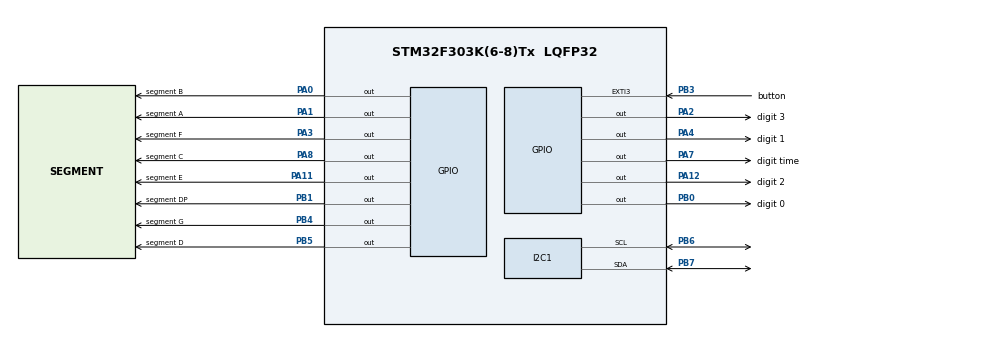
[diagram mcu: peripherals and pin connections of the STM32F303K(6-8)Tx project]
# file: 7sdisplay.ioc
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Mcu.Family=STM32F3
Mcu.Name=STM32F303K(6-8)Tx
Mcu.Package=LQFP32
NVIC.EXTI3_IRQn=true\:0\:0\:false\:false\:true\:true\:true
NVIC.I2C1_EV_IRQn=true\:0\:0\:false\:false\:true\:true\:true
NVIC.PriorityGroup=NVIC_PRIORITYGROUP_4
PA0.GPIO_Label=segment B
PA0.Signal=GPIO_Output
PA1.GPIO_Label=segment A
PA1.Signal=GPIO_Output
PA11.GPIO_Label=segment E
PA11.Signal=GPIO_Output
PA12.GPIO_Label=digit 2
PA12.Signal=GPIO_Output
PA2.GPIO_Label=digit 3
PA2.Signal=GPIO_Output
PA3.GPIO_Label=segment F
PA3.Signal=GPIO_Output
PA4.GPIO_Label=digit 1
PA4.Signal=GPIO_Output
PA7.GPIO_Label=digit time
PA7.Signal=GPIO_Output
PA8.GPIO_Label=segment C
PA8.Signal=GPIO_Output
PB0.GPIO_Label=digit 0
PB0.Signal=GPIO_Output
PB1.GPIO_Label=segment DP
PB1.Signal=GPIO_Output
PB3.GPIO_Label=button
PB3.Signal=GPXTI3
PB4.GPIO_Label=segment G
PB4.Signal=GPIO_Output
PB5.GPIO_Label=segment D
PB5.Signal=GPIO_Output
PB6.Mode=I2C
PB6.Signal=I2C1_SCL
PB7.Mode=I2C
PB7.Signal=I2C1_SDA
ProjectManager.HeapSize=0x200
ProjectManager.StackSize=0x400
ProjectManager.TargetToolchain=STM32CubeIDE
RCC.AHBFreq_Value=8000000
RCC.APB1Freq_Value=8000000
RCC.APB2Freq_Value=8000000
RCC.CortexFreq_Value=8000000
RCC.HSE_VALUE=8000000
RCC.HSI_VALUE=8000000
RCC.SYSCLKFreq_VALUE=8000000
board=custom

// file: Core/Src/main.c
/* USER CODE BEGIN Header */
/**
 ******************************************************************************
 * @file           : main.c
 * @brief          : Main program body
 ******************************************************************************
 * @attention
 *
 * <h2><center>&copy; Copyright (c) 2020 STMicroelectronics.
 * All rights reserved.</center></h2>
 *
 * This software component is licensed by ST under BSD 3-Clause license,
 * the "License"; You may not use this file except in compliance with the
 * License. You may obtain a copy of the License at:
 *                        opensource.org/licenses/BSD-3-Clause
 *
 ******************************************************************************
 */
/* USER CODE END Header */

#include "main.h"

void SystemClock_Config(void);

int main(void)
{

	/* MCU Configuration--------------------------------------------------------*/

	/* Reset of all peripherals, Initializes the Flash interface and the Systick. */

	LL_APB2_GRP1_EnableClock(LL_APB2_GRP1_PERIPH_SYSCFG);
	LL_APB1_GRP1_EnableClock(LL_APB1_GRP1_PERIPH_PWR);

	NVIC_SetPriorityGrouping(NVIC_PRIORITYGROUP_4);

	/* System interrupt init*/

	/* Configure the system clock */
	SystemClock_Config();

	/* Initialize all configured peripherals */
	MX_GPIO_Init();
	MX_I2C1_Init();
	/* USER CODE BEGIN 2 */
	LBS25HB_init();
	lis3mdl_init();
	state_init();
	/* USER CODE END 2 */

	/* Infinite loop */
	while (1)
	{

		processToDisplay();

	}
}

void SystemClock_Config(void)
{
	LL_FLASH_SetLatency(LL_FLASH_LATENCY_0);
	while(LL_FLASH_GetLatency()!= LL_FLASH_LATENCY_0)
	{
	}
	LL_RCC_HSI_Enable();

	/* Wait till HSI is ready */
	while(LL_RCC_HSI_IsReady() != 1)
	{

	}
	LL_RCC_HSI_SetCalibTrimming(16);
	LL_RCC_SetAHBPrescaler(LL_RCC_SYSCLK_DIV_1);
	LL_RCC_SetAPB1Prescaler(LL_RCC_APB1_DIV_1);
	LL_RCC_SetAPB2Prescaler(LL_RCC_APB1_DIV_1);
	LL_RCC_SetSysClkSource(LL_RCC_SYS_CLKSOURCE_HSI);

	/* Wait till System clock is ready */
	while(LL_RCC_GetSysClkSource() != LL_RCC_SYS_CLKSOURCE_STATUS_HSI)
	{

	}
	LL_Init1msTick(8000000);
	LL_SetSystemCoreClock(8000000);
	LL_RCC_SetI2CClockSource(LL_RCC_I2C1_CLKSOURCE_HSI);
}

void Error_Handler(void)
{
}

/************************ (C) COPYRIGHT STMicroelectronics *****END OF FILE****/
